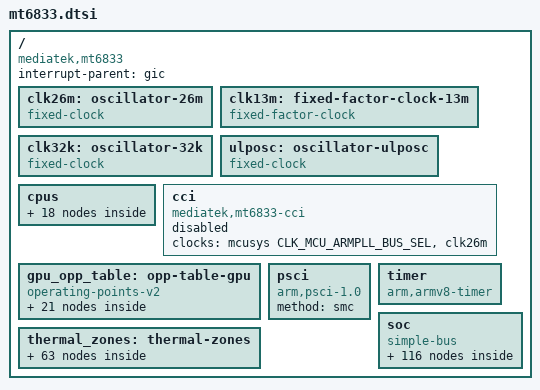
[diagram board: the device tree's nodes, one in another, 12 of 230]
// SPDX-License-Identifier: (GPL-2.0-only OR MIT)
/*
 * MediaTek MT6833 (Dimensity 700)
 */

#include <dt-bindings/clock/mediatek,mt6833-clk.h>
#include <dt-bindings/interrupt-controller/arm-gic.h>
#include <dt-bindings/interrupt-controller/irq.h>
#include <dt-bindings/memory/mediatek,mt6833-memory-port.h>
#include <dt-bindings/phy/phy.h>
#include <dt-bindings/power/mediatek,mt6833-power.h>
#include <dt-bindings/reset/mediatek,mt6833-resets.h>
#include <dt-bindings/thermal/mediatek,lvts-thermal.h>
#include <dt-bindings/thermal/thermal.h>

/ {
	compatible = "mediatek,mt6833";
	interrupt-parent = <&gic>;
	#address-cells = <2>;
	#size-cells = <2>;

	clk26m: oscillator-26m {
		compatible = "fixed-clock";
		#clock-cells = <0>;
		clock-frequency = <26000000>;
		clock-output-names = "clk26m";
	};

	clk13m: fixed-factor-clock-13m {
		compatible = "fixed-factor-clock";
		#clock-cells = <0>;
		clocks = <&clk26m>;
		clock-div = <2>;
		clock-mult = <1>;
		clock-output-names = "clk13m";
	};

	clk32k: oscillator-32k {
		compatible = "fixed-clock";
		#clock-cells = <0>;
		clock-frequency = <32768>;
		clock-output-names = "clk32k";
	};

	ulposc: oscillator-ulposc {
		compatible = "fixed-clock";
		#clock-cells = <0>;
		clock-frequency = <260000000>;
		clock-output-names = "ulposc";
	};

	cpus {
		#address-cells = <1>;
		#size-cells = <0>;

		cpu0: cpu@0 {
			device_type = "cpu";
			compatible = "arm,cortex-a55";
			reg = <0x000>;
			enable-method = "psci";
			clocks = <&mcusys CLK_MCU_ARMPLL_LL_SEL>, <&clk26m>;
			clock-names = "cpu", "intermediate";
			capacity-dmips-mhz = <405>;
			dynamic-power-coefficient = <85>;
			mediatek,cci = <&cci>;
			#cooling-cells = <2>;
		};

		cpu1: cpu@100 {
			device_type = "cpu";
			compatible = "arm,cortex-a55";
			reg = <0x100>;
			enable-method = "psci";
			clocks = <&mcusys CLK_MCU_ARMPLL_LL_SEL>, <&clk26m>;
			clock-names = "cpu", "intermediate";
			capacity-dmips-mhz = <405>;
			dynamic-power-coefficient = <85>;
			mediatek,cci = <&cci>;
			#cooling-cells = <2>;
		};

		cpu2: cpu@200 {
			device_type = "cpu";
			compatible = "arm,cortex-a55";
			reg = <0x200>;
			enable-method = "psci";
			clocks = <&mcusys CLK_MCU_ARMPLL_LL_SEL>, <&clk26m>;
			clock-names = "cpu", "intermediate";
			capacity-dmips-mhz = <405>;
			dynamic-power-coefficient = <85>;
			mediatek,cci = <&cci>;
			#cooling-cells = <2>;
		};

		cpu3: cpu@300 {
			device_type = "cpu";
			compatible = "arm,cortex-a55";
			reg = <0x300>;
			enable-method = "psci";
			clocks = <&mcusys CLK_MCU_ARMPLL_LL_SEL>, <&clk26m>;
			clock-names = "cpu", "intermediate";
			capacity-dmips-mhz = <405>;
			dynamic-power-coefficient = <85>;
			mediatek,cci = <&cci>;
			#cooling-cells = <2>;
		};

		cpu4: cpu@400 {
			device_type = "cpu";
			compatible = "arm,cortex-a55";
			reg = <0x400>;
			enable-method = "psci";
			clocks = <&mcusys CLK_MCU_ARMPLL_LL_SEL>, <&clk26m>;
			clock-names = "cpu", "intermediate";
			capacity-dmips-mhz = <405>;
			dynamic-power-coefficient = <85>;
			mediatek,cci = <&cci>;
			#cooling-cells = <2>;
		};

		cpu5: cpu@500 {
			device_type = "cpu";
			compatible = "arm,cortex-a55";
			reg = <0x500>;
			enable-method = "psci";
			clocks = <&mcusys CLK_MCU_ARMPLL_LL_SEL>, <&clk26m>;
			clock-names = "cpu", "intermediate";
			capacity-dmips-mhz = <405>;
			dynamic-power-coefficient = <85>;
			mediatek,cci = <&cci>;
			#cooling-cells = <2>;
		};

		cpu6: cpu@600 {
			device_type = "cpu";
			compatible = "arm,cortex-a76";
			reg = <0x600>;
			enable-method = "psci";
			clocks = <&mcusys CLK_MCU_ARMPLL_BL_SEL>, <&clk26m>;
			clock-names = "cpu", "intermediate";
			capacity-dmips-mhz = <1024>;
			dynamic-power-coefficient = <275>;
			mediatek,cci = <&cci>;
			#cooling-cells = <2>;
		};

		cpu7: cpu@700 {
			device_type = "cpu";
			compatible = "arm,cortex-a76";
			reg = <0x700>;
			enable-method = "psci";
			clocks = <&mcusys CLK_MCU_ARMPLL_BL_SEL>, <&clk26m>;
			clock-names = "cpu", "intermediate";
			capacity-dmips-mhz = <1024>;
			dynamic-power-coefficient = <275>;
			mediatek,cci = <&cci>;
			#cooling-cells = <2>;
		};

		cpu-map {
			cluster0 {
				core0 {
					cpu = <&cpu0>;
				};
				core1 {
					cpu = <&cpu1>;
				};
				core2 {
					cpu = <&cpu2>;
				};
				core3 {
					cpu = <&cpu3>;
				};
				core4 {
					cpu = <&cpu4>;
				};
				core5 {
					cpu = <&cpu5>;
				};
				core6 {
					cpu = <&cpu6>;
				};
				core7 {
					cpu = <&cpu7>;
				};
			};
		};
	};

	/* Its OPPs depend on the bin, so they come with the board. */
	cci: cci {
		compatible = "mediatek,mt6833-cci";
		clocks = <&mcusys CLK_MCU_ARMPLL_BUS_SEL>, <&clk26m>;
		clock-names = "cci", "intermediate";
		status = "disabled";
	};

	/*
	 * MediaTek's GPU OPPs up to 790 MHz, which every MT6833 bin runs (MT6833M
	 * stops there), at MediaTek's voltages: all at or below 0.75 V, where
	 * MediaTek keeps the GPU SRAM at 0.75 V.
	 */
	gpu_opp_table: opp-table-gpu {
		compatible = "operating-points-v2";

		opp-390000000 {
			opp-hz = /bits/ 64 <390000000>;
			opp-microvolt = <575000>;
		};

		opp-415000000 {
			opp-hz = /bits/ 64 <415000000>;
			opp-microvolt = <581250>;
		};

		opp-441000000 {
			opp-hz = /bits/ 64 <441000000>;
			opp-microvolt = <587500>;
		};

		opp-467000000 {
			opp-hz = /bits/ 64 <467000000>;
			opp-microvolt = <593750>;
		};

		opp-493000000 {
			opp-hz = /bits/ 64 <493000000>;
			opp-microvolt = <600000>;
		};

		opp-519000000 {
			opp-hz = /bits/ 64 <519000000>;
			opp-microvolt = <606250>;
		};

		opp-545000000 {
			opp-hz = /bits/ 64 <545000000>;
			opp-microvolt = <612500>;
		};

		opp-570000000 {
			opp-hz = /bits/ 64 <570000000>;
			opp-microvolt = <618750>;
		};

		opp-596000000 {
			opp-hz = /bits/ 64 <596000000>;
			opp-microvolt = <625000>;
		};

		opp-622000000 {
			opp-hz = /bits/ 64 <622000000>;
			opp-microvolt = <631250>;
		};

		opp-648000000 {
			opp-hz = /bits/ 64 <648000000>;
			opp-microvolt = <637500>;
		};

		opp-674000000 {
			opp-hz = /bits/ 64 <674000000>;
			opp-microvolt = <643750>;
		};

		opp-700000000 {
			opp-hz = /bits/ 64 <700000000>;
			opp-microvolt = <650000>;
		};

		opp-711000000 {
			opp-hz = /bits/ 64 <711000000>;
			opp-microvolt = <656250>;
		};

		opp-722000000 {
			opp-hz = /bits/ 64 <722000000>;
			opp-microvolt = <662500>;
		};

		opp-733000000 {
			opp-hz = /bits/ 64 <733000000>;
			opp-microvolt = <668750>;
		};

		opp-745000000 {
			opp-hz = /bits/ 64 <745000000>;
			opp-microvolt = <675000>;
		};

		opp-756000000 {
			opp-hz = /bits/ 64 <756000000>;
			opp-microvolt = <681250>;
		};

		opp-767000000 {
			opp-hz = /bits/ 64 <767000000>;
			opp-microvolt = <687500>;
		};

		opp-778000000 {
			opp-hz = /bits/ 64 <778000000>;
			opp-microvolt = <693750>;
		};

		opp-790000000 {
			opp-hz = /bits/ 64 <790000000>;
			opp-microvolt = <700000>;
		};
	};

	psci {
		compatible = "arm,psci-1.0";
		method = "smc";
	};

	thermal_zones: thermal-zones {
		cpu-little0-thermal {
			polling-delay = <1000>;
			polling-delay-passive = <250>;
			thermal-sensors = <&lvts MT6833_LITTLE_CPU0>;

			trips {
				cpu_little0_alert: trip-alert {
					temperature = <85000>;
					hysteresis = <2000>;
					type = "passive";
				};

				cpu_little0_crit: trip-crit {
					temperature = <117000>;
					hysteresis = <2000>;
					type = "critical";
				};
			};

			cooling-maps {
				map0 {
					trip = <&cpu_little0_alert>;
					cooling-device = <&cpu0 THERMAL_NO_LIMIT THERMAL_NO_LIMIT>,
							 <&cpu1 THERMAL_NO_LIMIT THERMAL_NO_LIMIT>,
							 <&cpu2 THERMAL_NO_LIMIT THERMAL_NO_LIMIT>,
							 <&cpu3 THERMAL_NO_LIMIT THERMAL_NO_LIMIT>,
							 <&cpu4 THERMAL_NO_LIMIT THERMAL_NO_LIMIT>,
							 <&cpu5 THERMAL_NO_LIMIT THERMAL_NO_LIMIT>;
				};
			};
		};

		cpu-little1-thermal {
			polling-delay = <1000>;
			polling-delay-passive = <250>;
			thermal-sensors = <&lvts MT6833_LITTLE_CPU1>;

			trips {
				cpu_little1_alert: trip-alert {
					temperature = <85000>;
					hysteresis = <2000>;
					type = "passive";
				};

				cpu_little1_crit: trip-crit {
					temperature = <117000>;
					hysteresis = <2000>;
					type = "critical";
				};
			};

			cooling-maps {
				map0 {
					trip = <&cpu_little1_alert>;
					cooling-device = <&cpu0 THERMAL_NO_LIMIT THERMAL_NO_LIMIT>,
							 <&cpu1 THERMAL_NO_LIMIT THERMAL_NO_LIMIT>,
							 <&cpu2 THERMAL_NO_LIMIT THERMAL_NO_LIMIT>,
							 <&cpu3 THERMAL_NO_LIMIT THERMAL_NO_LIMIT>,
							 <&cpu4 THERMAL_NO_LIMIT THERMAL_NO_LIMIT>,
							 <&cpu5 THERMAL_NO_LIMIT THERMAL_NO_LIMIT>;
				};
			};
		};

		cpu-little2-thermal {
			polling-delay = <1000>;
			polling-delay-passive = <250>;
			thermal-sensors = <&lvts MT6833_LITTLE_CPU2>;

			trips {
				cpu_little2_alert: trip-alert {
					temperature = <85000>;
					hysteresis = <2000>;
					type = "passive";
				};

				cpu_little2_crit: trip-crit {
					temperature = <117000>;
					hysteresis = <2000>;
					type = "critical";
				};
			};

			cooling-maps {
				map0 {
					trip = <&cpu_little2_alert>;
					cooling-device = <&cpu0 THERMAL_NO_LIMIT THERMAL_NO_LIMIT>,
							 <&cpu1 THERMAL_NO_LIMIT THERMAL_NO_LIMIT>,
							 <&cpu2 THERMAL_NO_LIMIT THERMAL_NO_LIMIT>,
							 <&cpu3 THERMAL_NO_LIMIT THERMAL_NO_LIMIT>,
							 <&cpu4 THERMAL_NO_LIMIT THERMAL_NO_LIMIT>,
							 <&cpu5 THERMAL_NO_LIMIT THERMAL_NO_LIMIT>;
				};
			};
		};

		cpu-little3-thermal {
			polling-delay = <1000>;
			polling-delay-passive = <250>;
			thermal-sensors = <&lvts MT6833_LITTLE_CPU3>;

			trips {
				cpu_little3_alert: trip-alert {
					temperature = <85000>;
					hysteresis = <2000>;
					type = "passive";
				};

				cpu_little3_crit: trip-crit {
					temperature = <117000>;
					hysteresis = <2000>;
					type = "critical";
				};
			};

			cooling-maps {
				map0 {
					trip = <&cpu_little3_alert>;
					cooling-device = <&cpu0 THERMAL_NO_LIMIT THERMAL_NO_LIMIT>,
							 <&cpu1 THERMAL_NO_LIMIT THERMAL_NO_LIMIT>,
							 <&cpu2 THERMAL_NO_LIMIT THERMAL_NO_LIMIT>,
							 <&cpu3 THERMAL_NO_LIMIT THERMAL_NO_LIMIT>,
							 <&cpu4 THERMAL_NO_LIMIT THERMAL_NO_LIMIT>,
							 <&cpu5 THERMAL_NO_LIMIT THERMAL_NO_LIMIT>;
				};
			};
		};

		cpu-big0-thermal {
			polling-delay = <1000>;
			polling-delay-passive = <250>;
			thermal-sensors = <&lvts MT6833_BIG_CPU0>;

			trips {
				cpu_big0_alert: trip-alert {
					temperature = <85000>;
					hysteresis = <2000>;
					type = "passive";
				};

				cpu_big0_crit: trip-crit {
					temperature = <117000>;
					hysteresis = <2000>;
					type = "critical";
				};
			};

			cooling-maps {
				map0 {
					trip = <&cpu_big0_alert>;
					cooling-device = <&cpu6 THERMAL_NO_LIMIT THERMAL_NO_LIMIT>,
							 <&cpu7 THERMAL_NO_LIMIT THERMAL_NO_LIMIT>;
				};
			};
		};

		cpu-big1-thermal {
			polling-delay = <1000>;
			polling-delay-passive = <250>;
			thermal-sensors = <&lvts MT6833_BIG_CPU1>;

			trips {
				cpu_big1_alert: trip-alert {
					temperature = <85000>;
					hysteresis = <2000>;
					type = "passive";
				};

				cpu_big1_crit: trip-crit {
					temperature = <117000>;
					hysteresis = <2000>;
					type = "critical";
				};
			};

			cooling-maps {
				map0 {
					trip = <&cpu_big1_alert>;
					cooling-device = <&cpu6 THERMAL_NO_LIMIT THERMAL_NO_LIMIT>,
							 <&cpu7 THERMAL_NO_LIMIT THERMAL_NO_LIMIT>;
				};
			};
		};

		gpu0-thermal {
			polling-delay = <1000>;
			polling-delay-passive = <250>;
			thermal-sensors = <&lvts MT6833_GPU0>;

			trips {
				gpu0_alert: trip-alert {
					temperature = <85000>;
					hysteresis = <2000>;
					type = "passive";
				};

				gpu0_crit: trip-crit {
					temperature = <117000>;
					hysteresis = <2000>;
					type = "critical";
				};
			};

			cooling-maps {
				map0 {
					trip = <&gpu0_alert>;
					cooling-device = <&gpu THERMAL_NO_LIMIT THERMAL_NO_LIMIT>;
				};
			};
		};

		gpu1-thermal {
			polling-delay = <1000>;
			polling-delay-passive = <250>;
			thermal-sensors = <&lvts MT6833_GPU1>;

			trips {
				gpu1_alert: trip-alert {
					temperature = <85000>;
					hysteresis = <2000>;
					type = "passive";
				};

				gpu1_crit: trip-crit {
					temperature = <117000>;
					hysteresis = <2000>;
					type = "critical";
				};
			};

			cooling-maps {
				map0 {
					trip = <&gpu1_alert>;
					cooling-device = <&gpu THERMAL_NO_LIMIT THERMAL_NO_LIMIT>;
				};
			};
		};

		soc-thermal {
			polling-delay = <1000>;
			polling-delay-passive = <250>;
			thermal-sensors = <&lvts MT6833_SOC>;

			trips {
				soc_crit: trip-crit {
					temperature = <117000>;
					hysteresis = <2000>;
					type = "critical";
				};
			};
		};

		conn-thermal {
			polling-delay = <1000>;
			polling-delay-passive = <250>;
			thermal-sensors = <&lvts MT6833_CONN>;

			trips {
				conn_crit: trip-crit {
					temperature = <117000>;
					hysteresis = <2000>;
					type = "critical";
				};
			};
		};

		md-4g-thermal {
			polling-delay = <1000>;
			polling-delay-passive = <250>;
			thermal-sensors = <&lvts MT6833_MD_4G>;

			trips {
				md_4g_crit: trip-crit {
					temperature = <117000>;
					hysteresis = <2000>;
					type = "critical";
				};
			};
		};

		md-5g-thermal {
			polling-delay = <1000>;
			polling-delay-passive = <250>;
			thermal-sensors = <&lvts MT6833_MD_5G>;

			trips {
				md_5g_crit: trip-crit {
					temperature = <117000>;
					hysteresis = <2000>;
					type = "critical";
				};
			};
		};

		md-3g-thermal {
			polling-delay = <1000>;
			polling-delay-passive = <250>;
			thermal-sensors = <&lvts MT6833_MD_3G>;

			trips {
				md_3g_crit: trip-crit {
					temperature = <117000>;
					hysteresis = <2000>;
					type = "critical";
				};
			};
		};
	};

	timer: timer {
		compatible = "arm,armv8-timer";
		interrupt-parent = <&gic>;
		interrupts = <GIC_PPI 13 IRQ_TYPE_LEVEL_HIGH 0>,
			     <GIC_PPI 14 IRQ_TYPE_LEVEL_HIGH 0>,
			     <GIC_PPI 11 IRQ_TYPE_LEVEL_HIGH 0>,
			     <GIC_PPI 10 IRQ_TYPE_LEVEL_HIGH 0>;
		clock-frequency = <13000000>;
	};

	soc {
		#address-cells = <2>;
		#size-cells = <2>;
		compatible = "simple-bus";
		ranges;

		gic: interrupt-controller@c000000 {
			compatible = "arm,gic-v3";
			#interrupt-cells = <4>;
			#redistributor-regions = <1>;
			interrupt-parent = <&gic>;
			interrupt-controller;
			reg = <0 0x0c000000 0 0x40000>,
			      <0 0x0c040000 0 0x200000>;
			interrupts = <GIC_PPI 9 IRQ_TYPE_LEVEL_HIGH 0>;

			ppi-partitions {
				ppi_cluster0: interrupt-partition-0 {
					affinity = <&cpu0 &cpu1 &cpu2 &cpu3 &cpu4 &cpu5>;
				};

				ppi_cluster1: interrupt-partition-1 {
					affinity = <&cpu6 &cpu7>;
				};
			};
		};

		mcusys: syscon@c53a000 {
			compatible = "mediatek,mt6833-mcusys", "syscon";
			reg = <0 0x0c53a000 0 0x1000>;
			#clock-cells = <1>;
		};

		topckgen: syscon@10000000 {
			compatible = "mediatek,mt6833-topckgen", "syscon";
			reg = <0 0x10000000 0 0x1000>;
			#clock-cells = <1>;
		};

		infracfg_ao: syscon@10001000 {
			compatible = "mediatek,mt6833-infracfg-ao", "syscon";
			reg = <0 0x10001000 0 0x1000>;
			#clock-cells = <1>;
			#reset-cells = <1>;
		};

		pio: pinctrl@10005000 {
			compatible = "mediatek,mt6833-pinctrl";
			reg = <0 0x10005000 0 0x1000>,
			      <0 0x11c30000 0 0x1000>,
			      <0 0x11d10000 0 0x1000>,
			      <0 0x11d40000 0 0x1000>,
			      <0 0x11e20000 0 0x1000>,
			      <0 0x11e60000 0 0x1000>,
			      <0 0x11ea0000 0 0x1000>,
			      <0 0x1000b000 0 0x1000>;
			reg-names = "base", "rb", "bm", "br", "lm", "bl", "rt", "eint";
			gpio-controller;
			#gpio-cells = <2>;
			gpio-ranges = <&pio 0 0 210>;
			interrupt-controller;
			interrupts = <GIC_SPI 212 IRQ_TYPE_LEVEL_HIGH 0>;
			#interrupt-cells = <2>;
		};

		scpsys: syscon@10006000 {
			compatible = "mediatek,mt6833-scpsys", "syscon", "simple-mfd";
			reg = <0 0x10006000 0 0x1000>;

			/* System Power Manager */
			spm: power-controller {
				compatible = "mediatek,mt6833-power-controller";
				#address-cells = <1>;
				#size-cells = <0>;
				#power-domain-cells = <1>;

				/*
				 * Only the GPU's and the display's: Linux turns off the
				 * domains it knows of that nothing uses, and the bootloader
				 * leaves others on. The display's is one Linux takes as off
				 * at boot, so it never turns it off as unused while the
				 * bootloader's picture is still being scanned out of it.
				 * Linux powers these on at probe and turns off at late
				 * boot those nothing uses. DISP, which the bootloader
				 * scans its framebuffer out through, stays out until the
				 * display comes.
				 */
				mfg0: power-domain@MT6833_POWER_DOMAIN_MFG0 {
					reg = <MT6833_POWER_DOMAIN_MFG0>;
					#address-cells = <1>;
					#size-cells = <0>;
					#power-domain-cells = <1>;

					mfg1: power-domain@MT6833_POWER_DOMAIN_MFG1 {
						reg = <MT6833_POWER_DOMAIN_MFG1>;
						clocks = <&topckgen CLK_TOP_MFG_PLL_SEL>,
							 <&topckgen CLK_TOP_MFG_REF_SEL>;
						clock-names = "mfg", "alt";
						mediatek,infracfg = <&infracfg_ao>;
						mediatek,infracfg-nao = <&infra_bcrm>;
						#address-cells = <1>;
						#size-cells = <0>;
						#power-domain-cells = <1>;

						power-domain@MT6833_POWER_DOMAIN_MFG2 {
							reg = <MT6833_POWER_DOMAIN_MFG2>;
							#power-domain-cells = <0>;
						};

						power-domain@MT6833_POWER_DOMAIN_MFG3 {
							reg = <MT6833_POWER_DOMAIN_MFG3>;
							#power-domain-cells = <0>;
						};
					};
				};

				power-domain@MT6833_POWER_DOMAIN_DISP {
					reg = <MT6833_POWER_DOMAIN_DISP>;
					clocks = <&topckgen CLK_TOP_DISP_SEL>,
						 <&mmsys CLK_MM_SMI_INFRA>,
						 <&mmsys CLK_MM_SMI_COMMON>,
						 <&mmsys CLK_MM_SMI_GALS>,
						 <&mmsys CLK_MM_SMI_IOMMU>;
					clock-names = "disp", "disp-0", "disp-1", "disp-2",
						      "disp-3";
					mediatek,infracfg = <&infracfg_ao>;
					#power-domain-cells = <0>;
				};
				/*
				 * ISP, ISP2, IPE, VDEC, VENC and CAM hang off DISP in
				 * MediaTek's tree, which powers the multimedia bus they
				 * sit on: they go under it when it comes.
				 */
				power-domain@MT6833_POWER_DOMAIN_ISP {
					reg = <MT6833_POWER_DOMAIN_ISP>;
					clocks = <&topckgen CLK_TOP_IMG1_SEL>,
						 <&imgsys1 CLK_IMGSYS1_GALS>,
						 <&imgsys1 CLK_IMGSYS1_LARB9>;
					clock-names = "isp", "isp-0", "isp-1";
					mediatek,infracfg = <&infracfg_ao>;
					#power-domain-cells = <0>;
				};

				power-domain@MT6833_POWER_DOMAIN_ISP2 {
					reg = <MT6833_POWER_DOMAIN_ISP2>;
					clocks = <&topckgen CLK_TOP_IMG2_SEL>,
						 <&imgsys2 CLK_IMGSYS2_GALS>,
						 <&imgsys2 CLK_IMGSYS2_LARB9>,
						 <&imgsys2 CLK_IMGSYS2_LARB10>;
					clock-names = "isp2", "isp2-0", "isp2-1", "isp2-2";
					#power-domain-cells = <0>;
				};

				power-domain@MT6833_POWER_DOMAIN_IPE {
					reg = <MT6833_POWER_DOMAIN_IPE>;
					clocks = <&topckgen CLK_TOP_IPE_SEL>,
						 <&ipesys CLK_IPE_SMI_SUBCOM>,
						 <&ipesys CLK_IPE_GALS>,
						 <&ipesys CLK_IPE_LARB19>,
						 <&ipesys CLK_IPE_LARB20>;
					clock-names = "ipe", "ipe-0", "ipe-1", "ipe-2", "ipe-3";
					mediatek,infracfg = <&infracfg_ao>;
					#power-domain-cells = <0>;
				};

				power-domain@MT6833_POWER_DOMAIN_VDEC {
					reg = <MT6833_POWER_DOMAIN_VDEC>;
					clocks = <&topckgen CLK_TOP_VDEC_SEL>,
						 <&vdecsys CLK_VDE2_VDEC_CKEN>,
						 <&vdecsys CLK_VDE2_LARB1_CKEN>;
					clock-names = "vdec", "vdec-0", "vdec-1";
					mediatek,infracfg = <&infracfg_ao>;
					#power-domain-cells = <0>;
				};

				power-domain@MT6833_POWER_DOMAIN_VENC {
					reg = <MT6833_POWER_DOMAIN_VENC>;
					clocks = <&topckgen CLK_TOP_VENC_SEL>,
						 <&vencsys CLK_VEN1_CKE1_VENC>;
					clock-names = "venc", "venc-0";
					mediatek,infracfg = <&infracfg_ao>;
					#power-domain-cells = <0>;
				};

				power-domain@MT6833_POWER_DOMAIN_AUDIO {
					reg = <MT6833_POWER_DOMAIN_AUDIO>;
					clocks = <&topckgen CLK_TOP_AUD_INTBUS_SEL>,
						 <&infracfg_ao CLK_IFRAO_AUDIO_26M_BCLK>,
						 <&infracfg_ao CLK_IFRAO_AUDIO>;
					clock-names = "audio", "audio-0", "audio-1";
					mediatek,infracfg = <&infracfg_ao>;
					#power-domain-cells = <0>;
				};

				power-domain@MT6833_POWER_DOMAIN_CAM {
					reg = <MT6833_POWER_DOMAIN_CAM>;
					clocks = <&topckgen CLK_TOP_CAM_SEL>,
						 <&camsys CLK_CAM_M_LARB13>,
						 <&camsys CLK_CAM_M_LARB14>,
						 <&camsys CLK_CAM_M_CCU_GALS>,
						 <&camsys CLK_CAM_M_CAM2MM_GALS>;
					clock-names = "cam", "cam-0", "cam-1", "cam-2", "cam-3";
					mediatek,infracfg = <&infracfg_ao>;
					#address-cells = <1>;
					#size-cells = <0>;
					#power-domain-cells = <1>;

					power-domain@MT6833_POWER_DOMAIN_CAM_RAWA {
						reg = <MT6833_POWER_DOMAIN_CAM_RAWA>;
						clocks = <&camsys_rawa CLK_CAM_RA_LARBX>;
						clock-names = "cam_rawa-0";
						#power-domain-cells = <0>;
					};

					power-domain@MT6833_POWER_DOMAIN_CAM_RAWB {
						reg = <MT6833_POWER_DOMAIN_CAM_RAWB>;
						clocks = <&camsys_rawb CLK_CAM_RB_LARBX>;
						clock-names = "cam_rawb-0";
						#power-domain-cells = <0>;
					};
				};
			};
		};

		watchdog: watchdog@10007000 {
			compatible = "mediatek,mt6833-wdt";
			reg = <0 0x10007000 0 0x100>;
		};

		apmixedsys: syscon@1000c000 {
			compatible = "mediatek,mt6833-apmixedsys", "syscon";
			reg = <0 0x1000c000 0 0x1000>;
			#clock-cells = <1>;
		};

		fhctl: clock-controller@1000ce00 {
			compatible = "mediatek,mt6833-fhctl";
			reg = <0 0x1000ce00 0 0x200>;
			clocks = <&apmixedsys CLK_APMIXED_MFGPLL>;
		};

		keypad: keypad@10010000 {
			compatible = "mediatek,mt6833-keypad", "mediatek,mt6779-keypad";
			reg = <0 0x10010000 0 0x1000>;
			interrupts = <GIC_SPI 74 IRQ_TYPE_EDGE_RISING 0>;
			clocks = <&clk26m>;
			clock-names = "kpd";
			status = "disabled";
		};

		systimer: timer@10017000 {
			compatible = "mediatek,mt6833-timer", "mediatek,mt6765-timer";
			reg = <0 0x10017000 0 0x1000>;
			interrupts = <GIC_SPI 233 IRQ_TYPE_LEVEL_HIGH 0>;
			clocks = <&clk13m>;
		};

		pwrap: pwrap@10026000 {
			compatible = "mediatek,mt6833-pwrap";
			reg = <0 0x10026000 0 0x1000>;
			reg-names = "pwrap";
			interrupts = <GIC_SPI 220 IRQ_TYPE_LEVEL_HIGH 0>;
			clocks = <&infracfg_ao CLK_IFRAO_PMIC_AP>,
				 <&infracfg_ao CLK_IFRAO_PMIC_TMR>;
			clock-names = "spi", "wrap";
		};

		spmi: spmi@10027000 {
			compatible = "mediatek,mt6833-spmi", "mediatek,mt8195-spmi";
			reg = <0 0x10027000 0 0x900>,
			      <0 0x10029000 0 0x100>;
			reg-names = "pmif", "spmimst";
			clocks = <&infracfg_ao CLK_IFRAO_PMIC_AP>,
				 <&infracfg_ao CLK_IFRAO_PMIC_TMR>,
				 <&topckgen CLK_TOP_SPMI_MST_SEL>;
			clock-names = "pmif_sys_ck", "pmif_tmr_ck", "spmimst_clk_mux";
			#address-cells = <2>;
			#size-cells = <0>;
			status = "disabled";
		};

		pwm: pwm@10048000 {
			compatible = "mediatek,mt6833-pwm", "mediatek,mt8183-pwm";
			reg = <0 0x10048000 0 0x1000>;
			interrupts = <GIC_SPI 77 IRQ_TYPE_LEVEL_HIGH 0>;
			#pwm-cells = <2>;
			clocks = <&infracfg_ao CLK_IFRAO_PWM>,
				 <&infracfg_ao CLK_IFRAO_PWM_HCLK>,
				 <&infracfg_ao CLK_IFRAO_PWM1>,
				 <&infracfg_ao CLK_IFRAO_PWM2>,
				 <&infracfg_ao CLK_IFRAO_PWM3>,
				 <&infracfg_ao CLK_IFRAO_PWM4>;
			clock-names = "top", "main", "pwm1", "pwm2", "pwm3", "pwm4";
			status = "disabled";
		};

		cqdma: dma-controller@10212000 {
			compatible = "mediatek,mt6833-cqdma", "mediatek,mt6765-cqdma";
			reg = <0 0x10212000 0 0x80>, <0 0x10212100 0 0x80>,
			      <0 0x10212200 0 0x80>, <0 0x10212300 0 0x80>;
			interrupts = <GIC_SPI 154 IRQ_TYPE_LEVEL_HIGH 0>,
				     <GIC_SPI 155 IRQ_TYPE_LEVEL_HIGH 0>,
				     <GIC_SPI 156 IRQ_TYPE_LEVEL_HIGH 0>,
				     <GIC_SPI 157 IRQ_TYPE_LEVEL_HIGH 0>;
			clocks = <&infracfg_ao CLK_IFRAO_CQ_DMA>;
			clock-names = "cqdma";
			dma-channels = <4>;
			dma-requests = <10>;
			#dma-cells = <1>;
			status = "disabled";
		};

		apdma: dma-controller@10217a80 {
			compatible = "mediatek,mt6833-uart-dma", "mediatek,mt6835-uart-dma";
			reg = <0 0x10217a80 0 0x80>, <0 0x10217b00 0 0x80>,
			      <0 0x10217b80 0 0x80>, <0 0x10217c00 0 0x80>;
			interrupts = <GIC_SPI 146 IRQ_TYPE_LEVEL_HIGH 0>,
				     <GIC_SPI 147 IRQ_TYPE_LEVEL_HIGH 0>,
				     <GIC_SPI 148 IRQ_TYPE_LEVEL_HIGH 0>,
				     <GIC_SPI 149 IRQ_TYPE_LEVEL_HIGH 0>;
			clocks = <&infracfg_ao CLK_IFRAO_AP_DMA>;
			clock-names = "apdma";
			dma-requests = <4>;
			#dma-cells = <1>;
		};

		gce: mailbox@10228000 {
			compatible = "mediatek,mt6833-gce", "mediatek,mt6779-gce";
			reg = <0 0x10228000 0 0x4000>;
			interrupts = <GIC_SPI 203 IRQ_TYPE_LEVEL_HIGH 0>;
			#mbox-cells = <2>;
			clocks = <&infracfg_ao CLK_IFRAO_GCE>;
			clock-names = "gce";
		};

		auxadc: adc@11001000 {
			compatible = "mediatek,mt6833-auxadc", "mediatek,mt6765-auxadc";
			reg = <0 0x11001000 0 0x1000>;
			clocks = <&infracfg_ao CLK_IFRAO_AUXADC>;
			clock-names = "main";
			#io-channel-cells = <1>;
			status = "disabled";
		};

		infra_bcrm: syscon@10215000 {
			compatible = "mediatek,mt6833-infra-bcrm", "syscon";
			reg = <0 0x10215000 0 0x1000>;
		};

		uart0: serial@11002000 {
			compatible = "mediatek,mt6833-uart", "mediatek,mt6577-uart";
			reg = <0 0x11002000 0 0x1000>;
			interrupts = <GIC_SPI 109 IRQ_TYPE_LEVEL_HIGH 0>;
			clocks = <&clk26m>, <&infracfg_ao CLK_IFRAO_UART0>;
			clock-names = "baud", "bus";
			dmas = <&apdma 0>, <&apdma 1>;
			dma-names = "tx", "rx";
			status = "disabled";
		};

		uart1: serial@11003000 {
			compatible = "mediatek,mt6833-uart", "mediatek,mt6577-uart";
			reg = <0 0x11003000 0 0x1000>;
			interrupts = <GIC_SPI 110 IRQ_TYPE_LEVEL_HIGH 0>;
			clocks = <&clk26m>, <&infracfg_ao CLK_IFRAO_UART1>;
			clock-names = "baud", "bus";
			dmas = <&apdma 2>, <&apdma 3>;
			dma-names = "tx", "rx";
			status = "disabled";
		};

		imp_iic_wrap_c: clock-controller@11007000 {
			compatible = "mediatek,mt6833-imp-iic-wrap-c";
			reg = <0 0x11007000 0 0x1000>;
			#clock-cells = <1>;
		};

		spi0: spi@1100a000 {
			compatible = "mediatek,mt6833-spi", "mediatek,mt6765-spi";
			reg = <0 0x1100a000 0 0x100>;
			interrupts = <GIC_SPI 159 IRQ_TYPE_LEVEL_HIGH 0>;
			clocks = <&topckgen CLK_TOP_MAINPLL_D5_D4>,
				 <&topckgen CLK_TOP_SPI_SEL>,
				 <&infracfg_ao CLK_IFRAO_SPI0>;
			clock-names = "parent-clk", "sel-clk", "spi-clk";
			#address-cells = <1>;
			#size-cells = <0>;
			status = "disabled";
		};

		disp_pwm: pwm@1100e000 {
			compatible = "mediatek,mt6833-disp-pwm", "mediatek,mt8183-disp-pwm";
			reg = <0 0x1100e000 0 0x1000>;
			interrupts = <GIC_SPI 171 IRQ_TYPE_LEVEL_HIGH 0>;
			#pwm-cells = <2>;
			clocks = <&topckgen CLK_TOP_DISP_PWM_SEL>,
				 <&infracfg_ao CLK_IFRAO_DISP_PWM>;
			clock-names = "main", "mm";
			status = "disabled";
		};

		spi1: spi@11010000 {
			compatible = "mediatek,mt6833-spi", "mediatek,mt6765-spi";
			reg = <0 0x11010000 0 0x100>;
			interrupts = <GIC_SPI 160 IRQ_TYPE_LEVEL_HIGH 0>;
			clocks = <&topckgen CLK_TOP_MAINPLL_D5_D4>,
				 <&topckgen CLK_TOP_SPI_SEL>,
				 <&infracfg_ao CLK_IFRAO_SPI1>;
			clock-names = "parent-clk", "sel-clk", "spi-clk";
			#address-cells = <1>;
			#size-cells = <0>;
			status = "disabled";
		};

		spi2: spi@11012000 {
			compatible = "mediatek,mt6833-spi", "mediatek,mt6765-spi";
			reg = <0 0x11012000 0 0x100>;
			interrupts = <GIC_SPI 161 IRQ_TYPE_LEVEL_HIGH 0>;
			clocks = <&topckgen CLK_TOP_MAINPLL_D5_D4>,
				 <&topckgen CLK_TOP_SPI_SEL>,
				 <&infracfg_ao CLK_IFRAO_SPI2>;
			clock-names = "parent-clk", "sel-clk", "spi-clk";
			#address-cells = <1>;
			#size-cells = <0>;
			status = "disabled";
		};

		spi3: spi@11013000 {
			compatible = "mediatek,mt6833-spi", "mediatek,mt6765-spi";
			reg = <0 0x11013000 0 0x100>;
			interrupts = <GIC_SPI 162 IRQ_TYPE_LEVEL_HIGH 0>;
			clocks = <&topckgen CLK_TOP_MAINPLL_D5_D4>,
				 <&topckgen CLK_TOP_SPI_SEL>,
				 <&infracfg_ao CLK_IFRAO_SPI3>;
			clock-names = "parent-clk", "sel-clk", "spi-clk";
			#address-cells = <1>;
			#size-cells = <0>;
			status = "disabled";
		};

		spi4: spi@11018000 {
			compatible = "mediatek,mt6833-spi", "mediatek,mt6765-spi";
			reg = <0 0x11018000 0 0x100>;
			interrupts = <GIC_SPI 163 IRQ_TYPE_LEVEL_HIGH 0>;
			clocks = <&topckgen CLK_TOP_MAINPLL_D5_D4>,
				 <&topckgen CLK_TOP_SPI_SEL>,
				 <&infracfg_ao CLK_IFRAO_SPI4>;
			clock-names = "parent-clk", "sel-clk", "spi-clk";
			#address-cells = <1>;
			#size-cells = <0>;
			status = "disabled";
		};

		spi5: spi@11019000 {
			compatible = "mediatek,mt6833-spi", "mediatek,mt6765-spi";
			reg = <0 0x11019000 0 0x100>;
			interrupts = <GIC_SPI 164 IRQ_TYPE_LEVEL_HIGH 0>;
			clocks = <&topckgen CLK_TOP_MAINPLL_D5_D4>,
				 <&topckgen CLK_TOP_SPI_SEL>,
				 <&infracfg_ao CLK_IFRAO_SPI5>;
			clock-names = "parent-clk", "sel-clk", "spi-clk";
			#address-cells = <1>;
			#size-cells = <0>;
			status = "disabled";
		};

		spi6: spi@1101d000 {
			compatible = "mediatek,mt6833-spi", "mediatek,mt6765-spi";
			reg = <0 0x1101d000 0 0x100>;
			interrupts = <GIC_SPI 165 IRQ_TYPE_LEVEL_HIGH 0>;
			clocks = <&topckgen CLK_TOP_MAINPLL_D5_D4>,
				 <&topckgen CLK_TOP_SPI_SEL>,
				 <&infracfg_ao CLK_IFRAO_SPI6_CK>;
			clock-names = "parent-clk", "sel-clk", "spi-clk";
			#address-cells = <1>;
			#size-cells = <0>;
			status = "disabled";
		};

		spi7: spi@1101e000 {
			compatible = "mediatek,mt6833-spi", "mediatek,mt6765-spi";
			reg = <0 0x1101e000 0 0x100>;
			interrupts = <GIC_SPI 166 IRQ_TYPE_LEVEL_HIGH 0>;
			clocks = <&topckgen CLK_TOP_MAINPLL_D5_D4>,
				 <&topckgen CLK_TOP_SPI_SEL>,
				 <&infracfg_ao CLK_IFRAO_SPI7_CK>;
			clock-names = "parent-clk", "sel-clk", "spi-clk";
			#address-cells = <1>;
			#size-cells = <0>;
			status = "disabled";
		};

		lvts: thermal-sensor@1100b000 {
			compatible = "mediatek,mt6833-lvts";
			reg = <0 0x1100b000 0 0xc00>;
			interrupts = <GIC_SPI 169 IRQ_TYPE_LEVEL_HIGH 0>;
			clocks = <&infracfg_ao CLK_IFRAO_THERM>;
			resets = <&infracfg_ao MT6833_INFRA_RST0_LVTS_AP>;
			nvmem-cells = <&lvts_efuse_data>;
			nvmem-cell-names = "lvts-calib-data-1";
			#thermal-sensor-cells = <1>;
		};

		usb: usb@11200000 {
			compatible = "mediatek,mt6833-musb", "mediatek,mtk-musb";
			reg = <0 0x11200000 0 0x10000>;
			interrupts = <GIC_SPI 96 IRQ_TYPE_LEVEL_HIGH 0>;
			interrupt-names = "mc";
			clocks = <&infracfg_ao CLK_IFRAO_SSUSB>,
				 <&topckgen CLK_TOP_UNIVPLL_D5_D4>,
				 <&apmixedsys CLK_APMIXED_USBPLL>;
			clock-names = "main", "mcu", "univpll";
			phys = <&u2port0 PHY_TYPE_USB2>;
			status = "disabled";
		};

		audsys: clock-controller@11210000 {
			compatible = "mediatek,mt6833-audsys", "syscon";
			reg = <0 0x11210000 0 0x2000>;
			power-domains = <&spm MT6833_POWER_DOMAIN_AUDIO>;
			#clock-cells = <1>;
		};

		mmc1: mmc@11240000 {
			compatible = "mediatek,mt6833-mmc", "mediatek,mt8183-mmc";
			reg = <0 0x11240000 0 0x1000>, <0 0x11c70000 0 0x1000>;
			interrupts = <GIC_SPI 103 IRQ_TYPE_LEVEL_HIGH 0>;
			clocks = <&topckgen CLK_TOP_MSDC30_1_SEL>,
				 <&infracfg_ao CLK_IFRAO_MSDC1>,
				 <&infracfg_ao CLK_IFRAO_MSDC1_SRC>;
			clock-names = "source", "hclk", "source_cg";
			status = "disabled";
		};

		ufshci: ufshci@11270000 {
			compatible = "mediatek,mt6833-ufshci", "mediatek,mt8183-ufshci";
			reg = <0 0x11270000 0 0x2300>;
			interrupts = <GIC_SPI 105 IRQ_TYPE_LEVEL_HIGH 0>;
			clocks = <&infracfg_ao CLK_IFRAO_UFS>,
				 <&infracfg_ao CLK_IFRAO_UNIPRO_SYSCLK>,
				 <&infracfg_ao CLK_IFRAO_UFS_SAP_BCLK>,
				 <&infracfg_ao CLK_IFRAO_UFS_AES>;
			clock-names = "ufs", "unipro_sysclk", "unipro_mp_bclk", "ufs_aes";
			freq-table-hz = <0 0>, <0 0>, <0 0>, <0 0>;
			resets = <&infracfg_ao MT6833_INFRA_RST1_UFSHCI>,
				 <&infracfg_ao MT6833_INFRA_RST2_UNIPRO>,
				 <&infracfg_ao MT6833_INFRA_RST3_UFS_CRYPTO>;
			reset-names = "hci_rst", "unipro_rst", "crypto_rst";
			mediatek,ufs-disable-ah8;
			mediatek,ufs-disable-mcq;
			status = "disabled";
		};

		i2c3: i2c@11cb0000 {
			compatible = "mediatek,mt6833-i2c", "mediatek,mt8192-i2c";
			reg = <0 0x11cb0000 0 0x1000>,
			      <0 0x10217300 0 0x80>;
			interrupts = <GIC_SPI 115 IRQ_TYPE_LEVEL_HIGH 0>;
			clocks = <&imp_iic_wrap_e CLK_IMPE_I2C3_AP_CLOCK>,
				 <&infracfg_ao CLK_IFRAO_AP_DMA>;
			clock-names = "main", "dma";
			clock-div = <1>;
			#address-cells = <1>;
			#size-cells = <0>;
			status = "disabled";
		};

		efuse: efuse@11c10000 {
			compatible = "mediatek,mt6833-efuse", "mediatek,efuse";
			reg = <0 0x11c10000 0 0x1000>;
			#address-cells = <1>;
			#size-cells = <1>;

			lvts_efuse_data: lvts-calib@1c0 {
				reg = <0x1c0 0x58>;
			};

			csi0_rx_calib: csi-calib@1a4 {
				reg = <0x1a4 0x4>;
			};

			csi1_rx_calib: csi-calib@1a8 {
				reg = <0x1a8 0x4>;
			};

			csi2_rx_calib: csi-calib@1ac {
				reg = <0x1ac 0x4>;
			};
		};

		csi0_rx: phy@11c80000 {
			compatible = "mediatek,mt6833-csi-rx";
			reg = <0 0x11c80000 0 0x4000>;
			nvmem-cells = <&csi0_rx_calib>;
			nvmem-cell-names = "calibration";
			#phy-cells = <1>;
			status = "disabled";
		};

		csi1_rx: phy@11c84000 {
			compatible = "mediatek,mt6833-csi-rx";
			reg = <0 0x11c84000 0 0x4000>;
			nvmem-cells = <&csi1_rx_calib>;
			nvmem-cell-names = "calibration";
			#phy-cells = <1>;
			status = "disabled";
		};

		csi2_rx: phy@11c88000 {
			compatible = "mediatek,mt6833-csi-rx";
			reg = <0 0x11c88000 0 0x4000>;
			nvmem-cells = <&csi2_rx_calib>;
			nvmem-cell-names = "calibration";
			#phy-cells = <1>;
			status = "disabled";
		};

		imp_iic_wrap_e: clock-controller@11cb1000 {
			compatible = "mediatek,mt6833-imp-iic-wrap-e";
			reg = <0 0x11cb1000 0 0x1000>;
			#clock-cells = <1>;
		};

		i2c8: i2c@11d00000 {
			compatible = "mediatek,mt6833-i2c", "mediatek,mt8192-i2c";
			reg = <0 0x11d00000 0 0x1000>,
			      <0 0x10217780 0 0x180>;
			interrupts = <GIC_SPI 120 IRQ_TYPE_LEVEL_HIGH 0>;
			clocks = <&imp_iic_wrap_s CLK_IMPS_I3C8_AP_CLOCK>,
				 <&infracfg_ao CLK_IFRAO_AP_DMA>;
			clock-names = "main", "dma";
			clock-div = <1>;
			#address-cells = <1>;
			#size-cells = <0>;
			status = "disabled";
		};

		i2c9: i2c@11d01000 {
			compatible = "mediatek,mt6833-i2c", "mediatek,mt8192-i2c";
			reg = <0 0x11d01000 0 0x1000>,
			      <0 0x10217900 0 0x180>;
			interrupts = <GIC_SPI 121 IRQ_TYPE_LEVEL_HIGH 0>;
			clocks = <&imp_iic_wrap_s CLK_IMPS_I3C9_AP_CLOCK>,
				 <&infracfg_ao CLK_IFRAO_AP_DMA>;
			clock-names = "main", "dma";
			clock-div = <1>;
			#address-cells = <1>;
			#size-cells = <0>;
			status = "disabled";
		};

		imp_iic_wrap_s: clock-controller@11d02000 {
			compatible = "mediatek,mt6833-imp-iic-wrap-s";
			reg = <0 0x11d02000 0 0x1000>;
			#clock-cells = <1>;
		};

		i2c1: i2c@11d20000 {
			compatible = "mediatek,mt6833-i2c", "mediatek,mt8192-i2c";
			reg = <0 0x11d20000 0 0x1000>,
			      <0 0x10217100 0 0x80>;
			interrupts = <GIC_SPI 113 IRQ_TYPE_LEVEL_HIGH 0>;
			clocks = <&imp_iic_wrap_ws CLK_IMPWS_I2C1_AP_CLOCK>,
				 <&infracfg_ao CLK_IFRAO_AP_DMA>;
			clock-names = "main", "dma";
			clock-div = <1>;
			#address-cells = <1>;
			#size-cells = <0>;
			status = "disabled";
		};

		i2c2: i2c@11d21000 {
			compatible = "mediatek,mt6833-i2c", "mediatek,mt8192-i2c";
			reg = <0 0x11d21000 0 0x1000>,
			      <0 0x10217180 0 0x180>;
			interrupts = <GIC_SPI 114 IRQ_TYPE_LEVEL_HIGH 0>;
			clocks = <&imp_iic_wrap_ws CLK_IMPWS_I3C2_AP_CLOCK>,
				 <&infracfg_ao CLK_IFRAO_AP_DMA>;
			clock-names = "main", "dma";
			clock-div = <1>;
			#address-cells = <1>;
			#size-cells = <0>;
			status = "disabled";
		};

		i2c4: i2c@11d22000 {
			compatible = "mediatek,mt6833-i2c", "mediatek,mt8192-i2c";
			reg = <0 0x11d22000 0 0x1000>,
			      <0 0x10217380 0 0x180>;
			interrupts = <GIC_SPI 116 IRQ_TYPE_LEVEL_HIGH 0>;
			clocks = <&imp_iic_wrap_ws CLK_IMPWS_I3C4_AP_CLOCK>,
				 <&infracfg_ao CLK_IFRAO_AP_DMA>;
			clock-names = "main", "dma";
			clock-div = <1>;
			#address-cells = <1>;
			#size-cells = <0>;
			status = "disabled";
		};

		imp_iic_wrap_ws: clock-controller@11d23000 {
			compatible = "mediatek,mt6833-imp-iic-wrap-ws";
			reg = <0 0x11d23000 0 0x1000>;
			#clock-cells = <1>;
		};

		i2c0: i2c@11e00000 {
			compatible = "mediatek,mt6833-i2c", "mediatek,mt8192-i2c";
			reg = <0 0x11e00000 0 0x1000>,
			      <0 0x10217080 0 0x80>;
			interrupts = <GIC_SPI 112 IRQ_TYPE_LEVEL_HIGH 0>;
			clocks = <&imp_iic_wrap_w CLK_IMPW_I2C0_AP_CLOCK>,
				 <&infracfg_ao CLK_IFRAO_AP_DMA>;
			clock-names = "main", "dma";
			clock-div = <1>;
			#address-cells = <1>;
			#size-cells = <0>;
			status = "disabled";
		};

		i2c5: i2c@11e01000 {
			compatible = "mediatek,mt6833-i2c", "mediatek,mt8192-i2c";
			reg = <0 0x11e01000 0 0x1000>,
			      <0 0x10217500 0 0x80>;
			interrupts = <GIC_SPI 117 IRQ_TYPE_LEVEL_HIGH 0>;
			clocks = <&imp_iic_wrap_w CLK_IMPW_I2C5_AP_CLOCK>,
				 <&infracfg_ao CLK_IFRAO_AP_DMA>;
			clock-names = "main", "dma";
			clock-div = <1>;
			#address-cells = <1>;
			#size-cells = <0>;
			status = "disabled";
		};

		i2c7: i2c@11e02000 {
			compatible = "mediatek,mt6833-i2c", "mediatek,mt8192-i2c";
			reg = <0 0x11e02000 0 0x1000>,
			      <0 0x10217600 0 0x180>;
			interrupts = <GIC_SPI 119 IRQ_TYPE_LEVEL_HIGH 0>;
			clocks = <&imp_iic_wrap_w CLK_IMPW_I3C7_AP_CLOCK>,
				 <&infracfg_ao CLK_IFRAO_AP_DMA>;
			clock-names = "main", "dma";
			clock-div = <1>;
			#address-cells = <1>;
			#size-cells = <0>;
			status = "disabled";
		};

		imp_iic_wrap_w: clock-controller@11e03000 {
			compatible = "mediatek,mt6833-imp-iic-wrap-w";
			reg = <0 0x11e03000 0 0x1000>;
			#clock-cells = <1>;
		};

		u2phy: t-phy@11e40000 {
			compatible = "mediatek,mt6833-tphy", "mediatek,generic-tphy-v2";
			#address-cells = <1>;
			#size-cells = <1>;
			ranges = <0 0 0x11e40000 0x1000>;
			status = "disabled";

			u2port0: usb-phy@0 {
				reg = <0 0x700>;
				clocks = <&clk26m>;
				clock-names = "ref";
				#phy-cells = <1>;
			};
		};

		mipi_tx0: dsi-phy@11e50000 {
			compatible = "mediatek,mt6833-mipi-tx", "mediatek,mt8183-mipi-tx";
			reg = <0 0x11e50000 0 0x1000>;
			clocks = <&clk26m>;
			clock-output-names = "mipi_tx0_pll";
			#clock-cells = <0>;
			#phy-cells = <0>;
			status = "disabled";
		};

		i2c6: i2c@11f00000 {
			compatible = "mediatek,mt6833-i2c", "mediatek,mt8192-i2c";
			reg = <0 0x11f00000 0 0x1000>,
			      <0 0x10217580 0 0x80>;
			interrupts = <GIC_SPI 118 IRQ_TYPE_LEVEL_HIGH 0>;
			clocks = <&imp_iic_wrap_n CLK_IMPN_I2C6_AP_CLOCK>,
				 <&infracfg_ao CLK_IFRAO_AP_DMA>;
			clock-names = "main", "dma";
			clock-div = <1>;
			#address-cells = <1>;
			#size-cells = <0>;
			status = "disabled";
		};

		imp_iic_wrap_n: clock-controller@11f01000 {
			compatible = "mediatek,mt6833-imp-iic-wrap-n";
			reg = <0 0x11f01000 0 0x1000>;
			#clock-cells = <1>;
		};

		gpu: gpu@13000000 {
			compatible = "mediatek,mt6833-mali", "mediatek,mt8370-mali",
				     "arm,mali-valhall-jm";
			reg = <0 0x13000000 0 0x4000>;
			interrupts = <GIC_SPI 366 IRQ_TYPE_LEVEL_HIGH 0>,
				     <GIC_SPI 365 IRQ_TYPE_LEVEL_HIGH 0>,
				     <GIC_SPI 364 IRQ_TYPE_LEVEL_HIGH 0>;
			interrupt-names = "job", "mmu", "gpu";
			clocks = <&mfgcfg CLK_MFGCFG_BG3D>;
			operating-points-v2 = <&gpu_opp_table>;
			power-domains = <&spm MT6833_POWER_DOMAIN_MFG2>,
					<&spm MT6833_POWER_DOMAIN_MFG3>;
			power-domain-names = "core0", "core1";
			#cooling-cells = <2>;
			status = "disabled";
		};

		mfgcfg: clock-controller@13fbf000 {
			compatible = "mediatek,mt6833-mfgcfg";
			reg = <0 0x13fbf000 0 0x1000>;
			power-domains = <&spm MT6833_POWER_DOMAIN_MFG1>;
			#clock-cells = <1>;
		};

		mmsys: syscon@14000000 {
			compatible = "mediatek,mt6833-mmsys", "syscon";
			reg = <0 0x14000000 0 0x1000>;
			#clock-cells = <1>;
		};

		mutex: mutex@14001000 {
			compatible = "mediatek,mt6833-disp-mutex";
			reg = <0 0x14001000 0 0x1000>;
			interrupts = <GIC_SPI 253 IRQ_TYPE_LEVEL_HIGH 0>;
			clocks = <&mmsys CLK_MM_DISP_MUTEX0>;
			power-domains = <&spm MT6833_POWER_DOMAIN_DISP>;
			status = "disabled";
		};

		smi_common: smi@14002000 {
			compatible = "mediatek,mt6833-smi-common";
			reg = <0 0x14002000 0 0x1000>;
			clocks = <&mmsys CLK_MM_SMI_INFRA>, <&mmsys CLK_MM_SMI_COMMON>,
				 <&mmsys CLK_MM_SMI_GALS>, <&mmsys CLK_MM_SMI_IOMMU>;
			clock-names = "apb", "smi", "gals0", "gals1";
			power-domains = <&spm MT6833_POWER_DOMAIN_DISP>;
			status = "disabled";
		};

		larb0: larb@14003000 {
			compatible = "mediatek,mt6833-smi-larb";
			reg = <0 0x14003000 0 0x1000>;
			mediatek,larb-id = <0>;
			mediatek,smi = <&smi_common>;
			clocks = <&mmsys CLK_MM_SMI_INFRA>, <&mmsys CLK_MM_SMI_COMMON>;
			clock-names = "apb", "smi";
			power-domains = <&spm MT6833_POWER_DOMAIN_DISP>;
			status = "disabled";
		};

		larb1: larb@14004000 {
			compatible = "mediatek,mt6833-smi-larb";
			reg = <0 0x14004000 0 0x1000>;
			mediatek,larb-id = <1>;
			mediatek,smi = <&smi_common>;
			clocks = <&mmsys CLK_MM_SMI_INFRA>, <&mmsys CLK_MM_SMI_COMMON>;
			clock-names = "apb", "smi";
			power-domains = <&spm MT6833_POWER_DOMAIN_DISP>;
			status = "disabled";
		};

		ovl0: ovl@14005000 {
			compatible = "mediatek,mt6833-disp-ovl", "mediatek,mt8192-disp-ovl";
			reg = <0 0x14005000 0 0x1000>;
			interrupts = <GIC_SPI 255 IRQ_TYPE_LEVEL_HIGH 0>;
			clocks = <&mmsys CLK_MM_DISP_OVL0>;
			iommus = <&iommu M4U_PORT_L0_OVL_RDMA0_HDR>,
				 <&iommu M4U_PORT_L0_OVL_RDMA0>;
			power-domains = <&spm MT6833_POWER_DOMAIN_DISP>;
			status = "disabled";
		};

		ovl_2l0: ovl@14006000 {
			compatible = "mediatek,mt6833-disp-ovl-2l", "mediatek,mt8192-disp-ovl-2l";
			reg = <0 0x14006000 0 0x1000>;
			interrupts = <GIC_SPI 256 IRQ_TYPE_LEVEL_HIGH 0>;
			clocks = <&mmsys CLK_MM_DISP_OVL0_2L>;
			iommus = <&iommu M4U_PORT_L1_OVL_2L_RDMA0_HDR>,
				 <&iommu M4U_PORT_L1_OVL_2L_RDMA0>;
			power-domains = <&spm MT6833_POWER_DOMAIN_DISP>;
			status = "disabled";
		};

		rdma0: rdma@14007000 {
			compatible = "mediatek,mt6833-disp-rdma", "mediatek,mt8183-disp-rdma";
			reg = <0 0x14007000 0 0x1000>;
			interrupts = <GIC_SPI 257 IRQ_TYPE_LEVEL_HIGH 0>;
			clocks = <&mmsys CLK_MM_DISP_RDMA0>;
			iommus = <&iommu M4U_PORT_L1_DISP_RDMA0>;
			mediatek,rdma-fifo-size = <35840>;
			power-domains = <&spm MT6833_POWER_DOMAIN_DISP>;
			status = "disabled";
		};

		color0: color@14009000 {
			compatible = "mediatek,mt6833-disp-color", "mediatek,mt8173-disp-color";
			reg = <0 0x14009000 0 0x1000>;
			interrupts = <GIC_SPI 259 IRQ_TYPE_LEVEL_HIGH 0>;
			clocks = <&mmsys CLK_MM_DISP_COLOR0>;
			power-domains = <&spm MT6833_POWER_DOMAIN_DISP>;
			status = "disabled";
		};

		ccorr0: ccorr@1400b000 {
			compatible = "mediatek,mt6833-disp-ccorr", "mediatek,mt8183-disp-ccorr";
			reg = <0 0x1400b000 0 0x1000>;
			interrupts = <GIC_SPI 260 IRQ_TYPE_LEVEL_HIGH 0>;
			clocks = <&mmsys CLK_MM_DISP_CCORR0>;
			power-domains = <&spm MT6833_POWER_DOMAIN_DISP>;
			status = "disabled";
		};

		aal0: aal@1400c000 {
			compatible = "mediatek,mt6833-disp-aal", "mediatek,mt8183-disp-aal";
			reg = <0 0x1400c000 0 0x1000>;
			interrupts = <GIC_SPI 262 IRQ_TYPE_LEVEL_HIGH 0>;
			clocks = <&mmsys CLK_MM_DISP_AAL0>;
			power-domains = <&spm MT6833_POWER_DOMAIN_DISP>;
			status = "disabled";
		};

		gamma0: gamma@1400d000 {
			compatible = "mediatek,mt6833-disp-gamma", "mediatek,mt8183-disp-gamma";
			reg = <0 0x1400d000 0 0x1000>;
			interrupts = <GIC_SPI 263 IRQ_TYPE_LEVEL_HIGH 0>;
			clocks = <&mmsys CLK_MM_DISP_GAMMA0>;
			power-domains = <&spm MT6833_POWER_DOMAIN_DISP>;
			status = "disabled";
		};

		postmask0: postmask@1400e000 {
			compatible = "mediatek,mt6833-disp-postmask",
				     "mediatek,mt8192-disp-postmask";
			reg = <0 0x1400e000 0 0x1000>;
			interrupts = <GIC_SPI 264 IRQ_TYPE_LEVEL_HIGH 0>;
			clocks = <&mmsys CLK_MM_DISP_POSTMASK0>;
			power-domains = <&spm MT6833_POWER_DOMAIN_DISP>;
			status = "disabled";
		};

		dither0: dither@1400f000 {
			compatible = "mediatek,mt6833-disp-dither", "mediatek,mt8183-disp-dither";
			reg = <0 0x1400f000 0 0x1000>;
			interrupts = <GIC_SPI 265 IRQ_TYPE_LEVEL_HIGH 0>;
			clocks = <&mmsys CLK_MM_DISP_DITHER0>;
			power-domains = <&spm MT6833_POWER_DOMAIN_DISP>;
			status = "disabled";
		};

		dsi0: dsi@14013000 {
			compatible = "mediatek,mt6833-dsi", "mediatek,mt8183-dsi";
			reg = <0 0x14013000 0 0x1000>;
			interrupts = <GIC_SPI 269 IRQ_TYPE_LEVEL_HIGH 0>;
			clocks = <&mmsys CLK_MM_DSI0>,
				 <&mmsys CLK_MM_DSI0_DSI_CK_DOMAIN>,
				 <&mipi_tx0>;
			clock-names = "engine", "digital", "hs";
			phys = <&mipi_tx0>;
			phy-names = "dphy";
			power-domains = <&spm MT6833_POWER_DOMAIN_DISP>;
			status = "disabled";
		};

		iommu: iommu@14016000 {
			compatible = "mediatek,mt6833-iommu-mm";
			reg = <0 0x14016000 0 0x1000>;
			interrupts = <GIC_SPI 271 IRQ_TYPE_LEVEL_HIGH 0>;
			clocks = <&mmsys CLK_MM_SMI_IOMMU>;
			clock-names = "bclk";
			mediatek,larbs = <&larb0>, <&larb1>, <&larb13>;
			power-domains = <&spm MT6833_POWER_DOMAIN_DISP>;
			#iommu-cells = <1>;
			status = "disabled";
		};

		imgsys1: clock-controller@15020000 {
			compatible = "mediatek,mt6833-imgsys1";
			reg = <0 0x15020000 0 0x1000>;
			#clock-cells = <1>;
		};

		imgsys2: clock-controller@15820000 {
			compatible = "mediatek,mt6833-imgsys2";
			reg = <0 0x15820000 0 0x1000>;
			#clock-cells = <1>;
		};

		vdecsys: clock-controller@1602f000 {
			compatible = "mediatek,mt6833-vdecsys";
			reg = <0 0x1602f000 0 0x1000>;
			#clock-cells = <1>;
		};

		vencsys: clock-controller@17000000 {
			compatible = "mediatek,mt6833-vencsys";
			reg = <0 0x17000000 0 0x1000>;
			#clock-cells = <1>;
		};

		camsys: clock-controller@1a000000 {
			compatible = "mediatek,mt6833-camsys";
			reg = <0 0x1a000000 0 0x1000>;
			#clock-cells = <1>;
		};

		larb13: larb@1a001000 {
			compatible = "mediatek,mt6833-smi-larb";
			reg = <0 0x1a001000 0 0x1000>;
			mediatek,larb-id = <13>;
			mediatek,smi = <&smi_sub_common_cam0>;
			clocks = <&camsys CLK_CAM_M_LARB13>, <&camsys CLK_CAM_M_LARB13>;
			clock-names = "apb", "smi";
			power-domains = <&spm MT6833_POWER_DOMAIN_CAM>;
			status = "disabled";
		};

		seninf: seninf@1a004000 {
			compatible = "mediatek,mt6833-seninf";
			reg = <0 0x1a004000 0 0x6000>;
			clocks = <&camsys CLK_CAM_M_SENINF>,
				 <&topckgen CLK_TOP_SENINF_SEL>,
				 <&topckgen CLK_TOP_SENINF1_SEL>,
				 <&topckgen CLK_TOP_SENINF2_SEL>;
			clock-names = "camsys", "seninf", "seninf1", "seninf2";
			power-domains = <&spm MT6833_POWER_DOMAIN_CAM>;
			phys = <&csi0_rx 0>, <&csi0_rx 1>, <&csi0_rx 2>,
			       <&csi1_rx 0>, <&csi1_rx 1>, <&csi1_rx 2>,
			       <&csi2_rx 0>, <&csi2_rx 1>, <&csi2_rx 2>;
			phy-names = "csi0", "csi0a", "csi0b",
				    "csi1", "csi1a", "csi1b",
				    "csi2", "csi2a", "csi2b";
			status = "disabled";

			ports {
				#address-cells = <1>;
				#size-cells = <0>;

				/* cam_mux 5 (pad 11) */
				port@b {
					reg = <11>;

					seninf_camsv2: endpoint {
						remote-endpoint = <&camsv2_in>;
					};
				};
			};
		};

		smi_sub_common_cam0: smi@1a00d000 {
			compatible = "mediatek,mt6833-smi-sub-common";
			reg = <0 0x1a00d000 0 0x1000>;
			mediatek,smi = <&smi_common>;
			clocks = <&camsys CLK_CAM_M_LARB13>, <&camsys CLK_CAM_M_LARB13>,
				 <&camsys CLK_CAM_M_LARB13>;
			clock-names = "apb", "smi", "gals0";
			power-domains = <&spm MT6833_POWER_DOMAIN_CAM>;
			status = "disabled";
		};

		camsys_rawa: clock-controller@1a04f000 {
			compatible = "mediatek,mt6833-camsys-rawa";
			reg = <0 0x1a04f000 0 0x1000>;
			#clock-cells = <1>;
		};

		camsys_rawb: clock-controller@1a06f000 {
			compatible = "mediatek,mt6833-camsys-rawb";
			reg = <0 0x1a06f000 0 0x1000>;
			#clock-cells = <1>;
		};

		camsv2: camsv@1a092000 {
			compatible = "mediatek,mt6833-camsv";
			reg = <0 0x1a092000 0 0x1000>;
			interrupts = <GIC_SPI 327 IRQ_TYPE_LEVEL_HIGH 0>;
			clocks = <&camsys CLK_CAM_M_CAM>,
				 <&camsys CLK_CAM_M_CAMTG>,
				 <&camsys CLK_CAM_M_CAMSV1>;
			clock-names = "cam", "camtg", "camsv";
			iommus = <&iommu M4U_PORT_L13_CAM_CAMSV4>;
			power-domains = <&spm MT6833_POWER_DOMAIN_CAM>;
			status = "disabled";

			port {
				camsv2_in: endpoint {
					remote-endpoint = <&seninf_camsv2>;
				};
			};
		};

		ipesys: clock-controller@1b000000 {
			compatible = "mediatek,mt6833-ipesys";
			reg = <0 0x1b000000 0 0x1000>;
			#clock-cells = <1>;
		};

		mdpsys: clock-controller@1f000000 {
			compatible = "mediatek,mt6833-mdpsys";
			reg = <0 0x1f000000 0 0x1000>;
			#clock-cells = <1>;
		};
	};
};
